# N32H7xx register map
Vendor: Nationstech Ltd.; File version: 1.0
CPU: CM7 r1p1, little endian, MPU, FPU, 4 interrupt priority bits
Registers are 32-bit, read-write, reset 0x0 unless marked. A register's access mark holds for its fields unless they carry their own. Offsets are from the block's base; [hi:lo] are bit positions; lines under a group give offsets from that group; {n}, {i} and the like mark numbered series.

## SHRTIM1_Common — Super high resolution timer: Common functions
Base 0x400D8380
Same registers: SHRTIM2_Common 0x400D9380
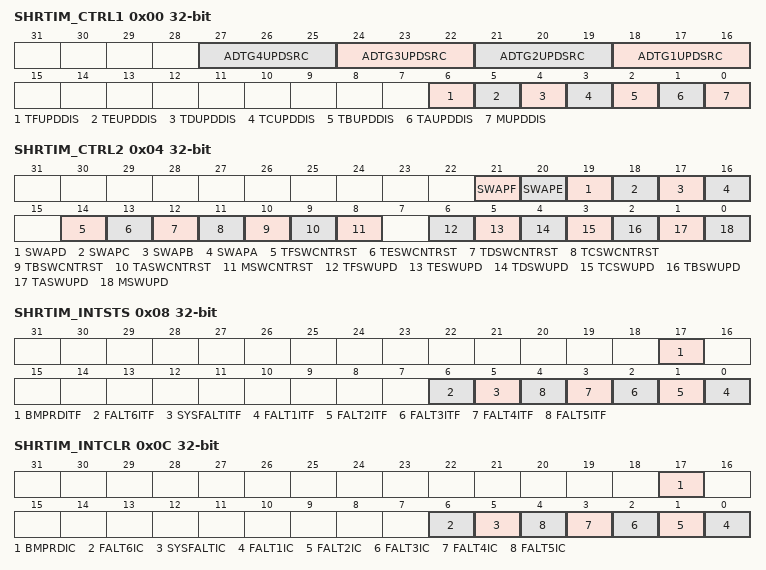
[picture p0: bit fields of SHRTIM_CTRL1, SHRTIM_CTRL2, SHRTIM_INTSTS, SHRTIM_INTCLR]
0x00 SHRTIM_CTRL1 — SHRTIM control register 1
  [3n+15:3n+13] ADTG{n}UPDSRC (n=1..4), [6] TFUPDDIS, [5] TEUPDDIS, [4] TDUPDDIS, [3] TCUPDDIS, [2] TBUPDDIS, [1] TAUPDDIS, [0] MUPDDIS
0x04 SHRTIM_CTRL2 — SHRTIM control register 2
  [21] SWAPF, [20] SWAPE, [19] SWAPD, [18] SWAPC, [17] SWAPB, [16] SWAPA, [14] TFSWCNTRST, [13] TESWCNTRST, [12] TDSWCNTRST, [11] TCSWCNTRST, [10] TBSWCNTRST, [9] TASWCNTRST, [8] MSWCNTRST, [6] TFSWUPD, [5] TESWUPD, [4] TDSWUPD, [3] TCSWUPD, [2] TBSWUPD, [1] TASWUPD, [0] MSWUPD
0x08 SHRTIM_INTSTS ro — SHRTIM interrupt status register
  [17] BMPRDITF, [6] FALT6ITF, [5] SYSFALTITF, [n-1] FALT{n}ITF (n=1..5)
0x0C SHRTIM_INTCLR wo — SHRTIM interrupt clear register
  [17] BMPRDIC, [6] FALT6IC, [5] SYSFALTIC, [n-1] FALT{n}IC (n=1..5)
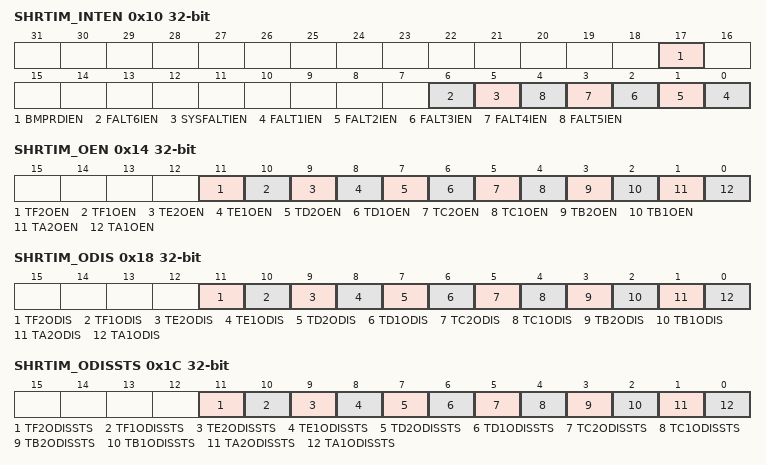
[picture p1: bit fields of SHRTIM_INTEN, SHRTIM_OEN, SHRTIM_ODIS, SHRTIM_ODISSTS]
0x10 SHRTIM_INTEN — SHRTIM interrupt enable register
  [17] BMPRDIEN, [6] FALT6IEN, [5] SYSFALTIEN, [n-1] FALT{n}IEN (n=1..5)
0x14 SHRTIM_OEN — SHRTIM output channel enable register
  [11] TF2OEN, [10] TF1OEN, [9] TE2OEN, [8] TE1OEN, [7] TD2OEN, [6] TD1OEN, [5] TC2OEN, [4] TC1OEN, [3] TB2OEN, [2] TB1OEN, [1] TA2OEN, [0] TA1OEN
0x18 SHRTIM_ODIS wo — SHRTIM output channel disable register
  [11] TF2ODIS, [10] TF1ODIS, [9] TE2ODIS, [8] TE1ODIS, [7] TD2ODIS, [6] TD1ODIS, [5] TC2ODIS, [4] TC1ODIS, [3] TB2ODIS, [2] TB1ODIS, [1] TA2ODIS, [0] TA1ODIS
0x1C SHRTIM_ODISSTS ro — SHRTIM output channel disable status register
  [11] TF2ODISSTS, [10] TF1ODISSTS, [9] TE2ODISSTS, [8] TE1ODISSTS, [7] TD2ODISSTS, [6] TD1ODISSTS, [5] TC2ODISSTS, [4] TC1ODISSTS, [3] TB2ODISSTS, [2] TB1ODISSTS, [1] TA2ODISSTS, [0] TA1ODISSTS
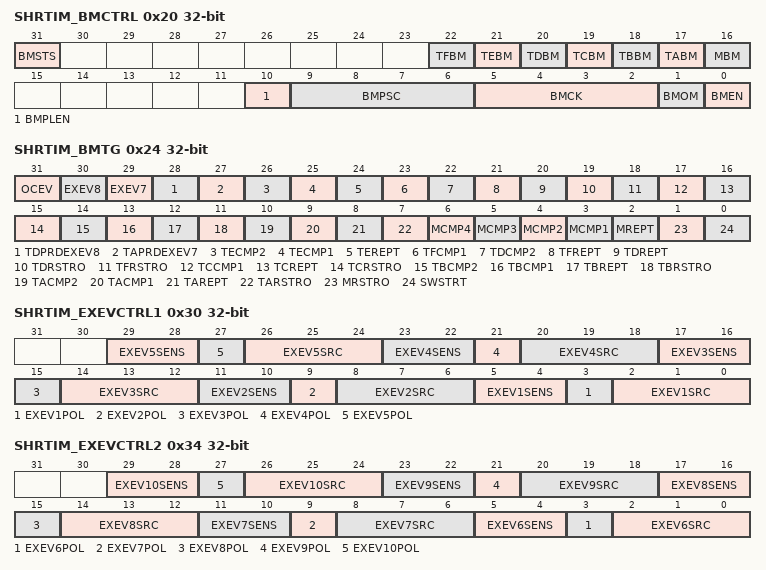
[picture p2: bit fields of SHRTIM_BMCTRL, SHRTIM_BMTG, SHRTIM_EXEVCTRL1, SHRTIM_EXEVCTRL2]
0x20 SHRTIM_BMCTRL — SHRTIM burst mode control register
  [31] BMSTS, [22] TFBM, [21] TEBM, [20] TDBM, [19] TCBM, [18] TBBM, [17] TABM, [16] MBM, [10] BMPLEN, [9:6] BMPSC, [5:2] BMCK, [1] BMOM, [0] BMEN
0x24 SHRTIM_BMTG — SHRTIM burst mode trigger register
  [31] OCEV, [30] EXEV8, [29] EXEV7, [28] TDPRDEXEV8, [27] TAPRDEXEV7, [26] TECMP2, [25] TECMP1, [24] TEREPT, [23] TFCMP1, [22] TDCMP2, [21] TFREPT, [20] TDREPT, [19] TDRSTRO, [18] TFRSTRO, [17] TCCMP1, [16] TCREPT, [15] TCRSTRO, [14] TBCMP2, [13] TBCMP1, [12] TBREPT, [11] TBRSTRO, [10] TACMP2, [9] TACMP1, [8] TAREPT, [7] TARSTRO, [n+2] MCMP{n} (n=1..4), [2] MREPT, [1] MRSTRO, [0] SWSTRT
0x28 SHRTIM_BMCMP — SHRTIM burst mode compare register
0x2C SHRTIM_BMPRD — SHRTIM burst mode period register
0x30 SHRTIM_EXEVCTRL1 — SHRTIM external event control register 1
  [6n-1:6n-2] EXEV{n}SENS (n=1..5), [6n-3] EXEV{n}POL (n=1..5), [6n-4:6n-6] EXEV{n}SRC (n=1..5)
0x34 SHRTIM_EXEVCTRL2 — SHRTIM external event control register 2
  [6n-31:6n-32] EXEV{n}SENS (n=6..10), [6n-33] EXEV{n}POL (n=6..10), [6n-34:6n-36] EXEV{n}SRC (n=6..10)
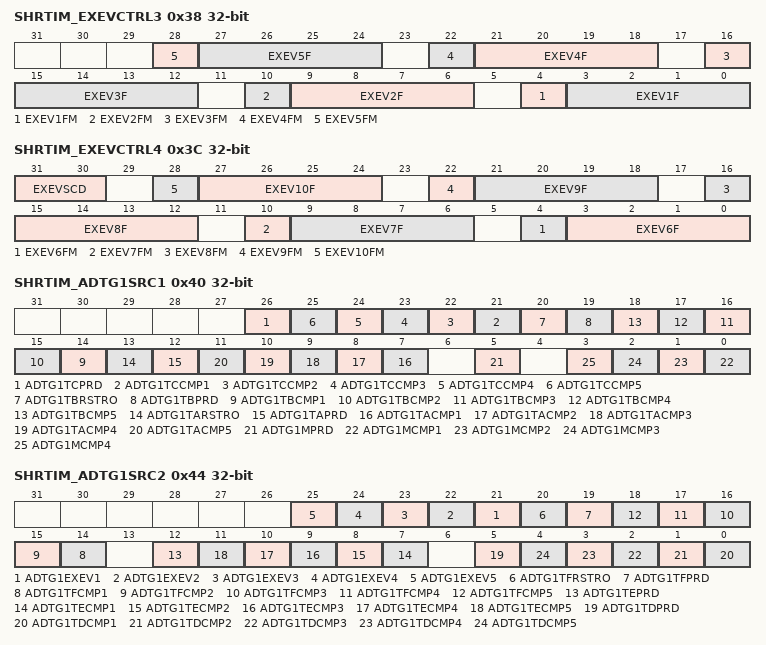
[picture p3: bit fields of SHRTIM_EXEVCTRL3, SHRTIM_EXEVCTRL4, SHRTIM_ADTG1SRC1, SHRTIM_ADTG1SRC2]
0x38 SHRTIM_EXEVCTRL3 — SHRTIM external event control register 4
  [6n-2] EXEV{n}FM (n=1..5), [6n-3:6n-6] EXEV{n}F (n=1..5)
0x3C SHRTIM_EXEVCTRL4 — SHRTIM external event control register 3
  [31:30] EXEVSCD, [6n-32] EXEV{n}FM (n=6..10), [6n-33:6n-36] EXEV{n}F (n=6..10)
0x40 SHRTIM_ADTG1SRC1 — SHRTIM ADC trigger 1's source group 1 register
  [26] ADTG1TCPRD, [n+20] ADTG1TCCMP{n} (n=1..5), [20] ADTG1TBRSTRO, [19] ADTG1TBPRD, [n+13] ADTG1TBCMP{n} (n=1..5), [13] ADTG1TARSTRO, [12] ADTG1TAPRD, [n+6] ADTG1TACMP{n} (n=1..5), [5] ADTG1MPRD, [n-1] ADTG1MCMP{n} (n=1..4)
0x44 SHRTIM_ADTG1SRC2 — SHRTIM ADC trigger 1's source group 2 register
  [n+20] ADTG1EXEV{n} (n=1..5), [20] ADTG1TFRSTRO, [19] ADTG1TFPRD, [n+13] ADTG1TFCMP{n} (n=1..5), [12] ADTG1TEPRD, [n+6] ADTG1TECMP{n} (n=1..5), [5] ADTG1TDPRD, [n-1] ADTG1TDCMP{n} (n=1..5)
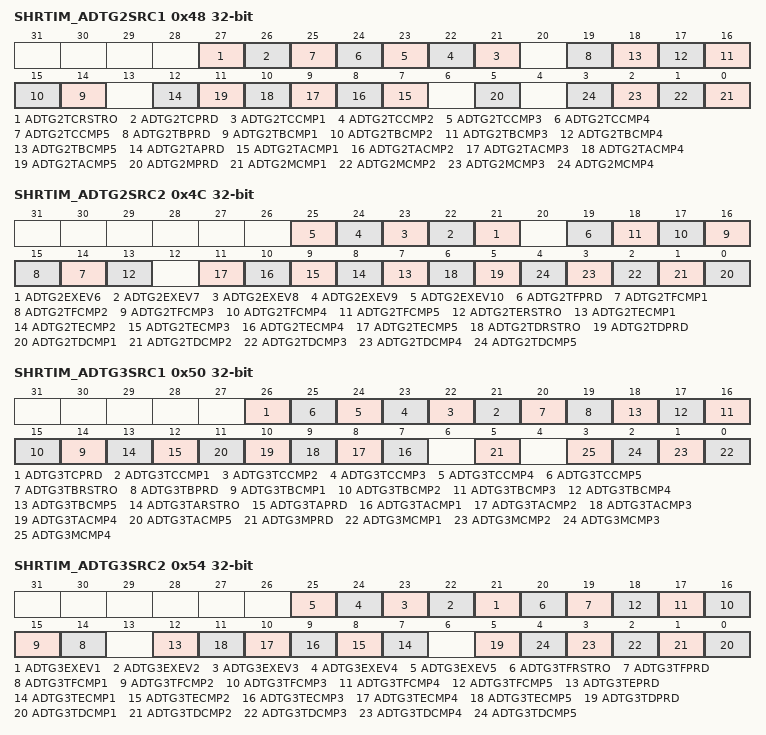
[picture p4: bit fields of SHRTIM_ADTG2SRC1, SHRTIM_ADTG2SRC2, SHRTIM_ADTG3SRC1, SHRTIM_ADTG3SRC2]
0x48 SHRTIM_ADTG2SRC1 — SHRTIM ADC trigger 2's source group 1 register
  [27] ADTG2TCRSTRO, [26] ADTG2TCPRD, [n+20] ADTG2TCCMP{n} (n=1..5), [19] ADTG2TBPRD, [n+13] ADTG2TBCMP{n} (n=1..5), [12] ADTG2TAPRD, [n+6] ADTG2TACMP{n} (n=1..5), [5] ADTG2MPRD, [n-1] ADTG2MCMP{n} (n=1..4)
0x4C SHRTIM_ADTG2SRC2 — SHRTIM ADC trigger 2's source group 2 register
  [n+15] ADTG2EXEV{n} (n=6..10), [19] ADTG2TFPRD, [n+13] ADTG2TFCMP{n} (n=1..5), [13] ADTG2TERSTRO, [n+6] ADTG2TECMP{n} (n=1..5), [6] ADTG2TDRSTRO, [5] ADTG2TDPRD, [n-1] ADTG2TDCMP{n} (n=1..5)
0x50 SHRTIM_ADTG3SRC1 — SHRTIM ADC trigger 3's source group 1 register
  [26] ADTG3TCPRD, [n+20] ADTG3TCCMP{n} (n=1..5), [20] ADTG3TBRSTRO, [19] ADTG3TBPRD, [n+13] ADTG3TBCMP{n} (n=1..5), [13] ADTG3TARSTRO, [12] ADTG3TAPRD, [n+6] ADTG3TACMP{n} (n=1..5), [5] ADTG3MPRD, [n-1] ADTG3MCMP{n} (n=1..4)
0x54 SHRTIM_ADTG3SRC2 — SHRTIM ADC trigger 3's source group 2 register
  [n+20] ADTG3EXEV{n} (n=1..5), [20] ADTG3TFRSTRO, [19] ADTG3TFPRD, [n+13] ADTG3TFCMP{n} (n=1..5), [12] ADTG3TEPRD, [n+6] ADTG3TECMP{n} (n=1..5), [5] ADTG3TDPRD, [n-1] ADTG3TDCMP{n} (n=1..5)
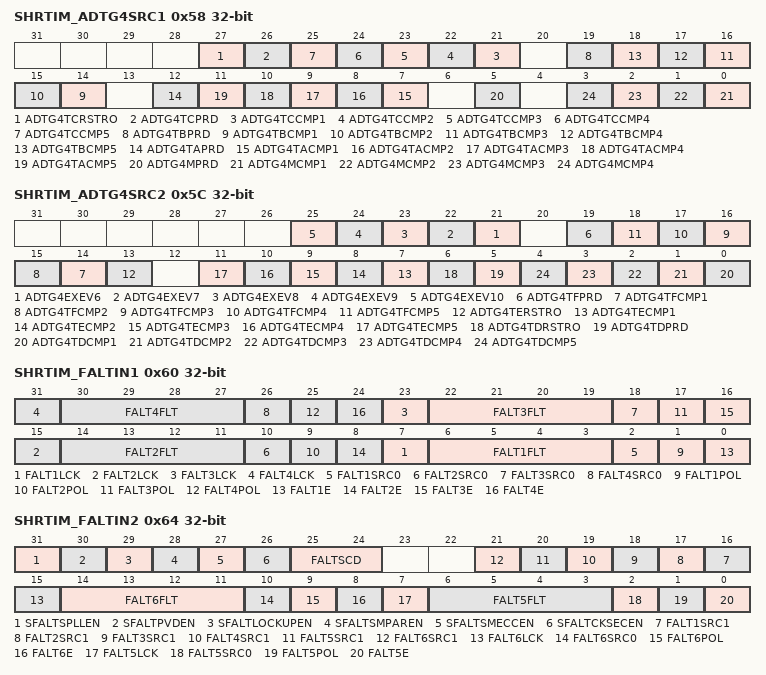
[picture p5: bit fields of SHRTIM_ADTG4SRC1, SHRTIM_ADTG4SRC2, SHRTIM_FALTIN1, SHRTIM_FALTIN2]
0x58 SHRTIM_ADTG4SRC1 — SHRTIM ADC trigger 4's source group 1 register
  [27] ADTG4TCRSTRO, [26] ADTG4TCPRD, [n+20] ADTG4TCCMP{n} (n=1..5), [19] ADTG4TBPRD, [n+13] ADTG4TBCMP{n} (n=1..5), [12] ADTG4TAPRD, [n+6] ADTG4TACMP{n} (n=1..5), [5] ADTG4MPRD, [n-1] ADTG4MCMP{n} (n=1..4)
0x5C SHRTIM_ADTG4SRC2 — SHRTIM ADC trigger 4's source group 2 register
  [n+15] ADTG4EXEV{n} (n=6..10), [19] ADTG4TFPRD, [n+13] ADTG4TFCMP{n} (n=1..5), [13] ADTG4TERSTRO, [n+6] ADTG4TECMP{n} (n=1..5), [6] ADTG4TDRSTRO, [5] ADTG4TDPRD, [n-1] ADTG4TDCMP{n} (n=1..5)
0x60 SHRTIM_FALTIN1 — SHRTIM fault input register 1
  [8n-1] FALT{n}LCK (n=1..4), [8n-2:8n-5] FALT{n}FLT (n=1..4), [8n-6] FALT{n}SRC0 (n=1..4), [8n-7] FALT{n}POL (n=1..4), [8n-8] FALT{n}E (n=1..4)
0x64 SHRTIM_FALTIN2 — SHRTIM fault input register 2
  [31] SFALTSPLLEN, [30] SFALTPVDEN, [29] SFALTLOCKUPEN, [28] SFALTSMPAREN, [27] SFALTSMECCEN, [26] SFALTCKSECEN, [25:24] FALTSCD, [n+15] FALT{n}SRC1 (n=1..6), [15] FALT6LCK, [14:11] FALT6FLT, [10] FALT6SRC0, [9] FALT6POL, [8] FALT6E, [7] FALT5LCK, [6:3] FALT5FLT, [2] FALT5SRC0, [1] FALT5POL, [0] FALT5E
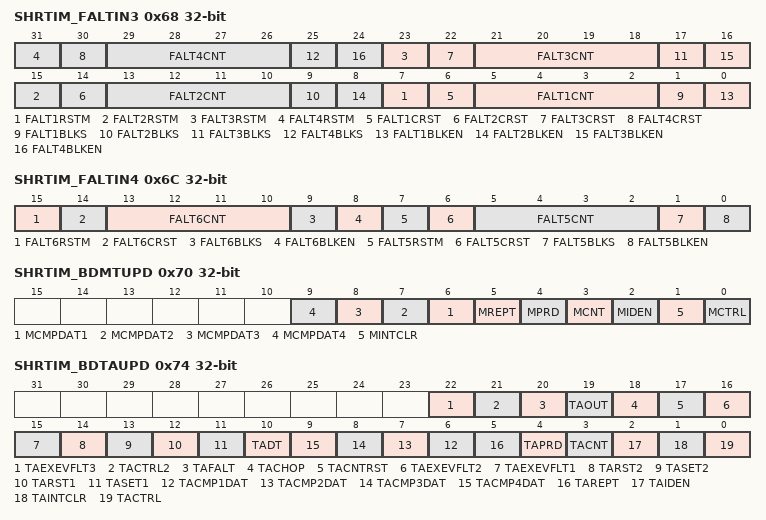
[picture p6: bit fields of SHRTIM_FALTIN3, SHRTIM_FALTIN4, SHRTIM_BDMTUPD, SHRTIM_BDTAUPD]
0x68 SHRTIM_FALTIN3 — SHRTIM fault input register 3
  [8n-1] FALT{n}RSTM (n=1..4), [8n-2] FALT{n}CRST (n=1..4), [8n-3:8n-6] FALT{n}CNT (n=1..4), [8n-7] FALT{n}BLKS (n=1..4), [8n-8] FALT{n}BLKEN (n=1..4)
0x6C SHRTIM_FALTIN4 — SHRTIM fault input register 4
  [15] FALT6RSTM, [14] FALT6CRST, [13:10] FALT6CNT, [9] FALT6BLKS, [8] FALT6BLKEN, [7] FALT5RSTM, [6] FALT5CRST, [5:2] FALT5CNT, [1] FALT5BLKS, [0] FALT5BLKEN
0x70 SHRTIM_BDMTUPD — SHRTIM burst DMA master timer update register
  [n+5] MCMPDAT{n} (n=1..4), [5] MREPT, [4] MPRD, [3] MCNT, [2] MIDEN, [1] MINTCLR, [0] MCTRL
0x74 SHRTIM_BDTAUPD — SHRTIM burst DMA timer A update register
  [22] TAEXEVFLT3, [21] TACTRL2, [20] TAFALT, [19] TAOUT, [18] TACHOP, [17] TACNTRST, [16] TAEXEVFLT2, [15] TAEXEVFLT1, [14] TARST2, [13] TASET2, [12] TARST1, [11] TASET1, [10] TADT, [n+5] TACMP{n}DAT (n=1..4), [5] TAREPT, [4] TAPRD, [3] TACNT, [2] TAIDEN, [1] TAINTCLR, [0] TACTRL
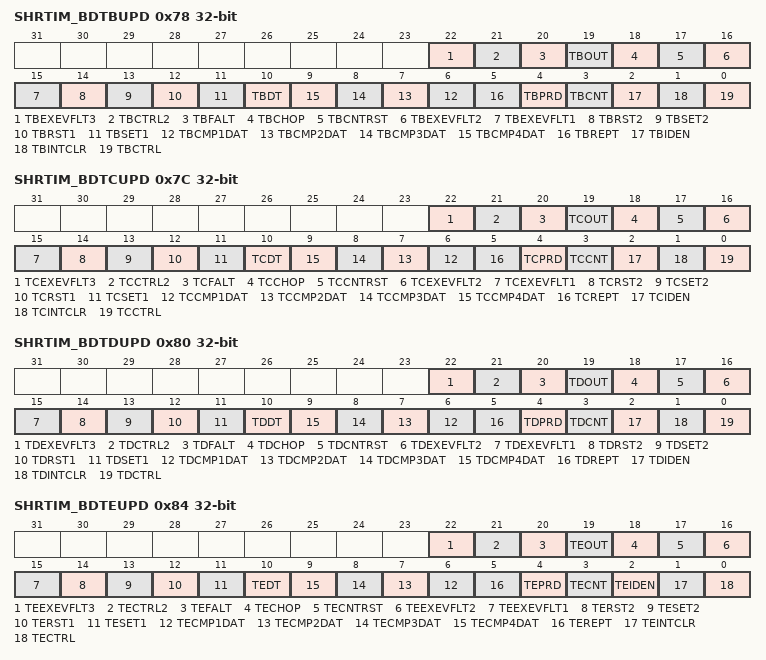
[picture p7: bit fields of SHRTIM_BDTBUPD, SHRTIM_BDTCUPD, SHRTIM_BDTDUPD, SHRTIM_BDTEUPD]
0x78 SHRTIM_BDTBUPD — SHRTIM burst DMA timer B update register
  [22] TBEXEVFLT3, [21] TBCTRL2, [20] TBFALT, [19] TBOUT, [18] TBCHOP, [17] TBCNTRST, [16] TBEXEVFLT2, [15] TBEXEVFLT1, [14] TBRST2, [13] TBSET2, [12] TBRST1, [11] TBSET1, [10] TBDT, [n+5] TBCMP{n}DAT (n=1..4), [5] TBREPT, [4] TBPRD, [3] TBCNT, [2] TBIDEN, [1] TBINTCLR, [0] TBCTRL
0x7C SHRTIM_BDTCUPD — SHRTIM burst DMA timer C update register
  [22] TCEXEVFLT3, [21] TCCTRL2, [20] TCFALT, [19] TCOUT, [18] TCCHOP, [17] TCCNTRST, [16] TCEXEVFLT2, [15] TCEXEVFLT1, [14] TCRST2, [13] TCSET2, [12] TCRST1, [11] TCSET1, [10] TCDT, [n+5] TCCMP{n}DAT (n=1..4), [5] TCREPT, [4] TCPRD, [3] TCCNT, [2] TCIDEN, [1] TCINTCLR, [0] TCCTRL
0x80 SHRTIM_BDTDUPD — SHRTIM burst DMA timer D update register
  [22] TDEXEVFLT3, [21] TDCTRL2, [20] TDFALT, [19] TDOUT, [18] TDCHOP, [17] TDCNTRST, [16] TDEXEVFLT2, [15] TDEXEVFLT1, [14] TDRST2, [13] TDSET2, [12] TDRST1, [11] TDSET1, [10] TDDT, [n+5] TDCMP{n}DAT (n=1..4), [5] TDREPT, [4] TDPRD, [3] TDCNT, [2] TDIDEN, [1] TDINTCLR, [0] TDCTRL
0x84 SHRTIM_BDTEUPD — SHRTIM burst DMA timer E update register
  [22] TEEXEVFLT3, [21] TECTRL2, [20] TEFALT, [19] TEOUT, [18] TECHOP, [17] TECNTRST, [16] TEEXEVFLT2, [15] TEEXEVFLT1, [14] TERST2, [13] TESET2, [12] TERST1, [11] TESET1, [10] TEDT, [n+5] TECMP{n}DAT (n=1..4), [5] TEREPT, [4] TEPRD, [3] TECNT, [2] TEIDEN, [1] TEINTCLR, [0] TECTRL
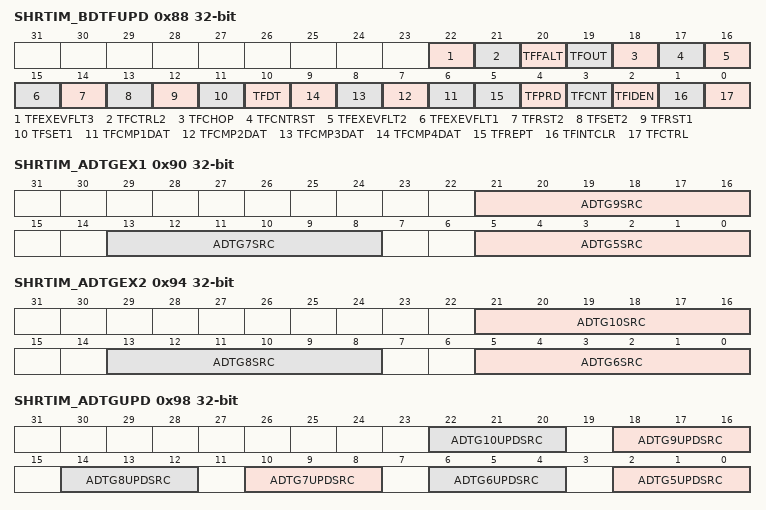
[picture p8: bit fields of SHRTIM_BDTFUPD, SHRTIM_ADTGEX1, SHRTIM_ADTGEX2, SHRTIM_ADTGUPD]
0x88 SHRTIM_BDTFUPD — SHRTIM burst DMA timer F update register
  [22] TFEXEVFLT3, [21] TFCTRL2, [20] TFFALT, [19] TFOUT, [18] TFCHOP, [17] TFCNTRST, [16] TFEXEVFLT2, [15] TFEXEVFLT1, [14] TFRST2, [13] TFSET2, [12] TFRST1, [11] TFSET1, [10] TFDT, [n+5] TFCMP{n}DAT (n=1..4), [5] TFREPT, [4] TFPRD, [3] TFCNT, [2] TFIDEN, [1] TFINTCLR, [0] TFCTRL
0x8C SHRTIM_BDDAT wo — SHRTIM burst DMA data register
  [31:0] BDMADATA
0x90 SHRTIM_ADTGEX1 — SHRTIM ADC extended trigger register 1
  [21:16] ADTG9SRC, [13:8] ADTG7SRC, [5:0] ADTG5SRC
0x94 SHRTIM_ADTGEX2 — SHRTIM ADC extended trigger register 2
  [21:16] ADTG10SRC, [13:8] ADTG8SRC, [5:0] ADTG6SRC
0x98 SHRTIM_ADTGUPD — SHRTIM ADC trigger update register
  [4n-18:4n-20] ADTG{n}UPDSRC (n=5..10)
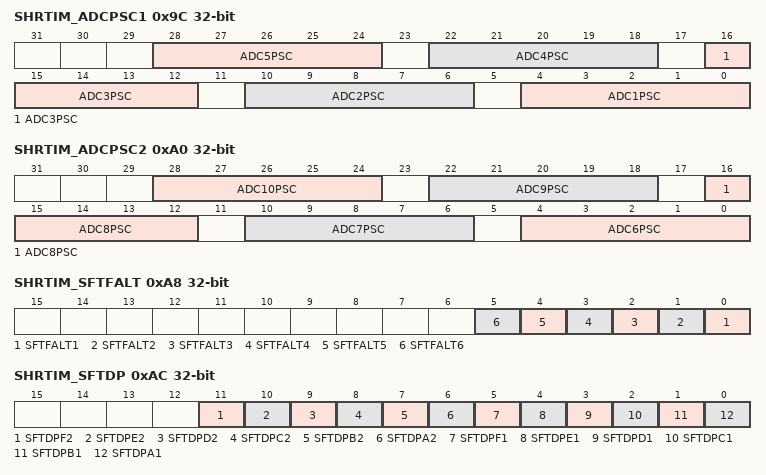
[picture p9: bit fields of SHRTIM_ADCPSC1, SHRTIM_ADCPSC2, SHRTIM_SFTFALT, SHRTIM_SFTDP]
0x9C SHRTIM_ADCPSC1 — SHRTIM ADC post scaler register 1
  [6n-2:6n-6] ADC{n}PSC (n=1..5)
0xA0 SHRTIM_ADCPSC2 — SHRTIM ADC post scaler register 2
  [6n-32:6n-36] ADC{n}PSC (n=6..10)
0xA8 SHRTIM_SFTFALT — SHRTIM soft fault trigger register
  [n-1] SFTFALT{n} (n=1..6)
0xAC SHRTIM_SFTDP — SHRTIM soft delayed protection trigger register
  [11] SFTDPF2, [10] SFTDPE2, [9] SFTDPD2, [8] SFTDPC2, [7] SFTDPB2, [6] SFTDPA2, [5] SFTDPF1, [4] SFTDPE1, [3] SFTDPD1, [2] SFTDPC1, [1] SFTDPB1, [0] SFTDPA1
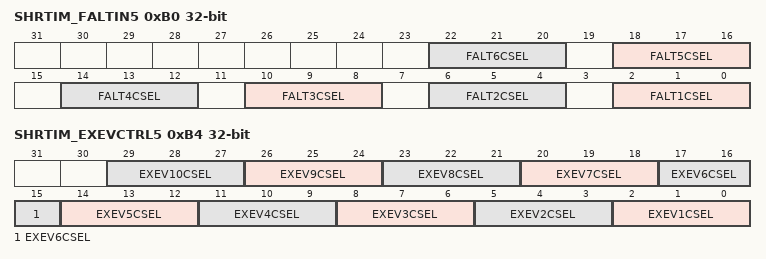
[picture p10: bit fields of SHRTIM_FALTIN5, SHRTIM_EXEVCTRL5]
0xB0 SHRTIM_FALTIN5 — SHRTIM fault input register 5
  [4n-2:4n-4] FALT{n}CSEL (n=1..6)
0xB4 SHRTIM_EXEVCTRL5 — SHRTIM external event control register 5
  [3n-1:3n-3] EXEV{n}CSEL (n=1..10)
0xB8 SHRTIM_EXTEND
  [31:30] AUXBYPA
